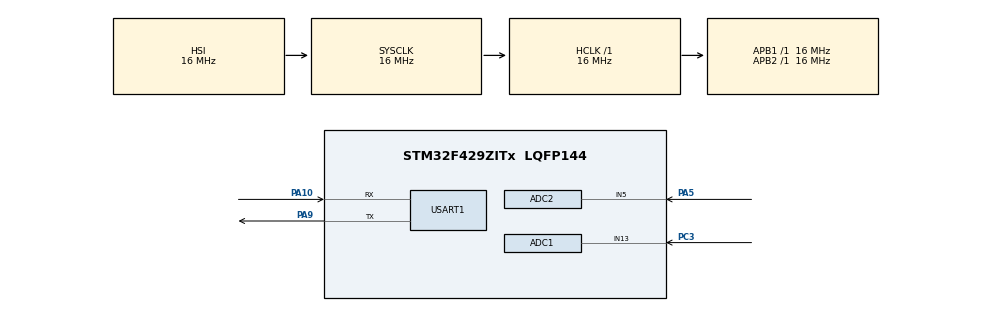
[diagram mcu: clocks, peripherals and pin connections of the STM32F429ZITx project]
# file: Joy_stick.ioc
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ADC1.Channel-3\#ChannelRegularConversion=ADC_CHANNEL_13
ADC1.NbrOfConversionFlag=1
ADC1.Rank-3\#ChannelRegularConversion=1
ADC1.Resolution=ADC_RESOLUTION_8B
ADC1.SamplingTime-3\#ChannelRegularConversion=ADC_SAMPLETIME_3CYCLES
ADC1.master=1
ADC2.Channel-0\#ChannelRegularConversion=ADC_CHANNEL_5
ADC2.NbrOfConversionFlag=1
ADC2.Rank-0\#ChannelRegularConversion=1
ADC2.Resolution=ADC_RESOLUTION_8B
ADC2.SamplingTime-0\#ChannelRegularConversion=ADC_SAMPLETIME_3CYCLES
Mcu.Family=STM32F4
Mcu.Name=STM32F429ZITx
Mcu.Package=LQFP144
NVIC.ADC_IRQn=true\:0\:0\:false\:false\:true\:true\:true\:true
NVIC.PriorityGroup=NVIC_PRIORITYGROUP_4
PA10.Mode=Asynchronous
PA10.Signal=USART1_RX
PA5.Signal=ADCx_IN5
PA9.Mode=Asynchronous
PA9.Signal=USART1_TX
PC3.Signal=ADCx_IN13
ProjectManager.HeapSize=0x200
ProjectManager.StackSize=0x400
ProjectManager.TargetToolchain=STM32CubeIDE
RCC.AHBFreq_Value=16000000
RCC.APB1Freq_Value=16000000
RCC.APB2Freq_Value=16000000
RCC.CortexFreq_Value=16000000
RCC.HSE_VALUE=25000000
RCC.HSI_VALUE=16000000
RCC.LSE_VALUE=32768
RCC.SYSCLKFreq_VALUE=16000000
RCC.VCOOutputFreq_Value=192000000
SH.ADCx_IN13.0=ADC1_IN13,IN13
SH.ADCx_IN5.0=ADC2_IN5,IN5
USART1.VirtualMode=VM_ASYNC
board=custom

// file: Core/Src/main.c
/* USER CODE BEGIN Header */
/**
  ******************************************************************************
  * @file           : main.c
  * @brief          : Main program body
  ******************************************************************************
  * @attention
  *
  * Copyright (c) 2025 STMicroelectronics.
  * All rights reserved.
  *
  * This software is licensed under terms that can be found in the LICENSE file
  * in the root directory of this software component.
  * If no LICENSE file comes with this software, it is provided AS-IS.
  *
  ******************************************************************************
  */
/* USER CODE END Header */
#include "main.h"
#include "string.h"

/* USER CODE BEGIN PD */
#define ADC_BUF_LEN 44096
/* USER CODE END PD */

ADC_HandleTypeDef hadc1;
ADC_HandleTypeDef hadc2;

UART_HandleTypeDef huart1;

/* USER CODE BEGIN PV */
uint8_t adc1_buf[ADC_BUF_LEN];
int adc1_count = 0;
/* USER CODE END PV */

void SystemClock_Config(void);
static void MX_GPIO_Init(void);
static void MX_USART1_UART_Init(void);
static void MX_ADC1_Init(void);
static void MX_ADC2_Init(void);

int main(void)
{

  /* MCU Configuration--------------------------------------------------------*/

  /* Reset of all peripherals, Initializes the Flash interface and the Systick. */
  HAL_Init();

  /* Configure the system clock */
  SystemClock_Config();

  /* Initialize all configured peripherals */
  MX_GPIO_Init();
  MX_USART1_UART_Init();
  MX_ADC1_Init();
  MX_ADC2_Init();
  /* USER CODE BEGIN 2 */
  HAL_ADC_Start_IT(&hadc1);
  /* USER CODE END 2 */

  /* Infinite loop */
  while (1)
  {
	 if(adc1_count >= 1000) {
		 char s[20];
		 int avg = 0;
		 while(adc1_count > 0) {
			 adc1_count--;
			 avg += adc1_buf[adc1_count];
		 }
		 avg /= 1000;
		 sprintf(s, "%3d\n", avg);
		 HAL_UART_Transmit(&huart1, s, 4, 10);
		 HAL_ADC_Start_IT(&hadc1);
	 } else {
//		 HAL_UART_Transmit(&huart1 ,"No data", 7, 10);
	 }
	 HAL_Delay(10);
  }
}

void SystemClock_Config(void)
{
  RCC_OscInitTypeDef RCC_OscInitStruct = {0};
  RCC_ClkInitTypeDef RCC_ClkInitStruct = {0};

  /** Configure the main internal regulator output voltage
  */
  __HAL_RCC_PWR_CLK_ENABLE();
  __HAL_PWR_VOLTAGESCALING_CONFIG(PWR_REGULATOR_VOLTAGE_SCALE3);

  /** Initializes the RCC Oscillators according to the specified parameters
  * in the RCC_OscInitTypeDef structure.
  */
  RCC_OscInitStruct.OscillatorType = RCC_OSCILLATORTYPE_HSI;
  RCC_OscInitStruct.HSIState = RCC_HSI_ON;
  RCC_OscInitStruct.HSICalibrationValue = RCC_HSICALIBRATION_DEFAULT;
  RCC_OscInitStruct.PLL.PLLState = RCC_PLL_NONE;
  if (HAL_RCC_OscConfig(&RCC_OscInitStruct) != HAL_OK)
  {
    Error_Handler();
  }

  /** Initializes the CPU, AHB and APB buses clocks
  */
  RCC_ClkInitStruct.ClockType = RCC_CLOCKTYPE_HCLK|RCC_CLOCKTYPE_SYSCLK
                              |RCC_CLOCKTYPE_PCLK1|RCC_CLOCKTYPE_PCLK2;
  RCC_ClkInitStruct.SYSCLKSource = RCC_SYSCLKSOURCE_HSI;
  RCC_ClkInitStruct.AHBCLKDivider = RCC_SYSCLK_DIV1;
  RCC_ClkInitStruct.APB1CLKDivider = RCC_HCLK_DIV1;
  RCC_ClkInitStruct.APB2CLKDivider = RCC_HCLK_DIV1;

  if (HAL_RCC_ClockConfig(&RCC_ClkInitStruct, FLASH_LATENCY_0) != HAL_OK)
  {
    Error_Handler();
  }
}

static void MX_ADC1_Init(void)
{

  ADC_ChannelConfTypeDef sConfig = {0};

  /** Configure the global features of the ADC (Clock, Resolution, Data Alignment and number of conversion)
  */
  hadc1.Instance = ADC1;
  hadc1.Init.ClockPrescaler = ADC_CLOCK_SYNC_PCLK_DIV2;
  hadc1.Init.Resolution = ADC_RESOLUTION_8B;
  hadc1.Init.ScanConvMode = DISABLE;
  hadc1.Init.ContinuousConvMode = DISABLE;
  hadc1.Init.DiscontinuousConvMode = DISABLE;
  hadc1.Init.ExternalTrigConvEdge = ADC_EXTERNALTRIGCONVEDGE_NONE;
  hadc1.Init.ExternalTrigConv = ADC_SOFTWARE_START;
  hadc1.Init.DataAlign = ADC_DATAALIGN_RIGHT;
  hadc1.Init.NbrOfConversion = 1;
  hadc1.Init.DMAContinuousRequests = DISABLE;
  hadc1.Init.EOCSelection = ADC_EOC_SINGLE_CONV;
  if (HAL_ADC_Init(&hadc1) != HAL_OK)
  {
    Error_Handler();
  }

  /** Configure for the selected ADC regular channel its corresponding rank in the sequencer and its sample time.
  */
  sConfig.Channel = ADC_CHANNEL_13;
  sConfig.Rank = 1;
  sConfig.SamplingTime = ADC_SAMPLETIME_3CYCLES;
  if (HAL_ADC_ConfigChannel(&hadc1, &sConfig) != HAL_OK)
  {
    Error_Handler();
  }

}

static void MX_ADC2_Init(void)
{

  ADC_ChannelConfTypeDef sConfig = {0};

  /** Configure the global features of the ADC (Clock, Resolution, Data Alignment and number of conversion)
  */
  hadc2.Instance = ADC2;
  hadc2.Init.ClockPrescaler = ADC_CLOCK_SYNC_PCLK_DIV2;
  hadc2.Init.Resolution = ADC_RESOLUTION_8B;
  hadc2.Init.ScanConvMode = DISABLE;
  hadc2.Init.ContinuousConvMode = DISABLE;
  hadc2.Init.DiscontinuousConvMode = DISABLE;
  hadc2.Init.ExternalTrigConvEdge = ADC_EXTERNALTRIGCONVEDGE_NONE;
  hadc2.Init.ExternalTrigConv = ADC_SOFTWARE_START;
  hadc2.Init.DataAlign = ADC_DATAALIGN_RIGHT;
  hadc2.Init.NbrOfConversion = 1;
  hadc2.Init.DMAContinuousRequests = DISABLE;
  hadc2.Init.EOCSelection = ADC_EOC_SINGLE_CONV;
  if (HAL_ADC_Init(&hadc2) != HAL_OK)
  {
    Error_Handler();
  }

  /** Configure for the selected ADC regular channel its corresponding rank in the sequencer and its sample time.
  */
  sConfig.Channel = ADC_CHANNEL_5;
  sConfig.Rank = 1;
  sConfig.SamplingTime = ADC_SAMPLETIME_3CYCLES;
  if (HAL_ADC_ConfigChannel(&hadc2, &sConfig) != HAL_OK)
  {
    Error_Handler();
  }

}

static void MX_USART1_UART_Init(void)
{

  huart1.Instance = USART1;
  huart1.Init.BaudRate = 115200;
  huart1.Init.WordLength = UART_WORDLENGTH_8B;
  huart1.Init.StopBits = UART_STOPBITS_1;
  huart1.Init.Parity = UART_PARITY_NONE;
  huart1.Init.Mode = UART_MODE_TX_RX;
  huart1.Init.HwFlowCtl = UART_HWCONTROL_NONE;
  huart1.Init.OverSampling = UART_OVERSAMPLING_16;
  if (HAL_UART_Init(&huart1) != HAL_OK)
  {
    Error_Handler();
  }

}

static void MX_GPIO_Init(void)
{

  /* GPIO Ports Clock Enable */
  __HAL_RCC_GPIOC_CLK_ENABLE();
  __HAL_RCC_GPIOA_CLK_ENABLE();

}

/* USER CODE BEGIN 4 */
void HAL_ADC_ConvCpltCallback(ADC_HandleTypeDef* hadc) {
	if(hadc == &hadc1) {
		adc1_buf[adc1_count] = HAL_ADC_GetValue(&hadc1);

		adc1_count++;
	}

	if(adc1_count < 1000) {
		HAL_ADC_Start_IT(&hadc1);
	}
}
/* USER CODE END 4 */

void Error_Handler(void)
{
  __disable_irq();
  while (1)
  {
  }
}
